# WBZ351 register map
Vendor: Microchip
Registers are 32-bit, read-write, reset 0x0 unless marked. A register's access mark holds for its fields unless they carry their own. Addresses are absolute, and some are shared; only a register's first bit layout is shown; [hi:lo] are bit positions; 'fields as' and 'values as' point back to an identical list.

## SILEX
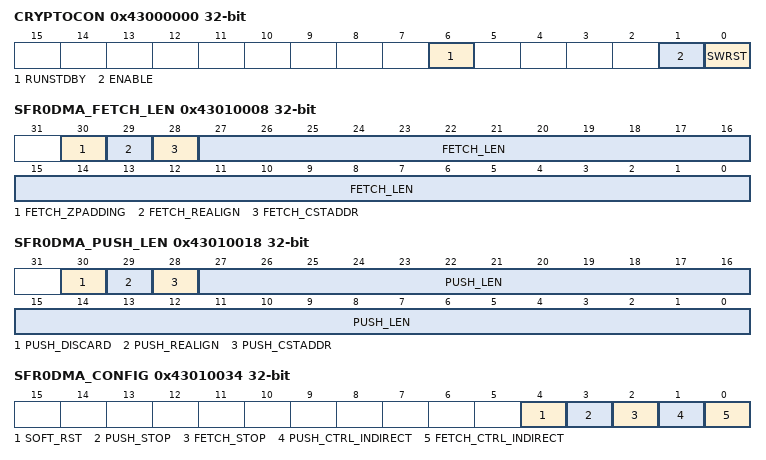
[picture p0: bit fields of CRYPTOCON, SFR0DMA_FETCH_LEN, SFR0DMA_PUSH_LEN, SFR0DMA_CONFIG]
0x43000000 CRYPTOCON
  [6] RUNSTDBY — Enable clock in idle mode
  [1] ENABLE — Enable clock to SILEX
  [0] SWRST — Software Reset
0x43010000 SFR0DMA_FETCH_ADDR_LSB
  [31:0] FETCH_ADDR_LSB
0x43010004 SFR0DMA_FETCH_ADDR_MSB
  [31:0] FETCH_ADDR_MSB
0x43010008 SFR0DMA_FETCH_LEN
  [30] FETCH_ZPADDING, [29] FETCH_REALIGN, [28] FETCH_CSTADDR, [27:0] FETCH_LEN
0x4301000C SFR0DMA_FETCH_TAG
  [31:0] FETCH_TAG
0x43010010 SFR0DMA_PUSH_ADDR_LSB
  [31:0] PUSH_ADDR_LSB
0x43010014 SFR0DMA_PUSH_ADDR_MSB
  [31:0] PUSH_ADDR_MSB
0x43010018 SFR0DMA_PUSH_LEN
  [30] PUSH_DISCARD, [29] PUSH_REALIGN, [28] PUSH_CSTADDR, [27:0] PUSH_LEN
0x4301001C SFR0DMA_INT_EN
  [31:0] INT_EN
0x43010020 SFR0DMA_INT_ENSET wo
  [31:0] INT_ENSET
0x43010024 SFR0DMA_INT_ENCLR wo
  [31:0] INT_ENCLR
0x43010028 SFR0DMA_INT_STATRAW ro
  [31:0] INT_STATRAW
0x4301002C SFR0DMA_INT_STAT ro
  [31:0] INT_STAT
0x43010030 SFR0DMA_INT_STATCLR wo
  [31:0] INT_STATCLR
0x43010034 SFR0DMA_CONFIG
  [4] SOFT_RST, [3] PUSH_STOP, [2] FETCH_STOP, [1] PUSH_CTRL_INDIRECT, [0] FETCH_CTRL_INDIRECT
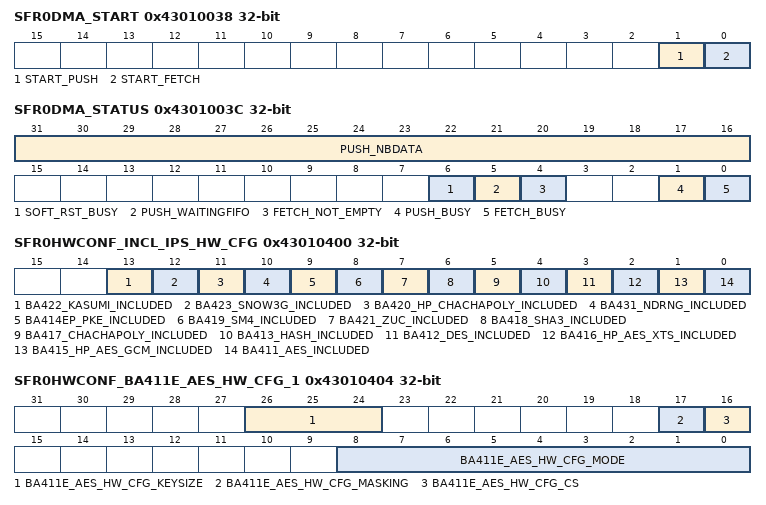
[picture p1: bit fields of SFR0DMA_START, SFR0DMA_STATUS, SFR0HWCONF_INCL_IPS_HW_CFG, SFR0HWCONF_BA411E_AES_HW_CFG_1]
0x43010038 SFR0DMA_START wo
  [1] START_PUSH, [0] START_FETCH
0x4301003C SFR0DMA_STATUS ro
  [31:16] PUSH_NBDATA, [6] SOFT_RST_BUSY, [5] PUSH_WAITINGFIFO, [4] FETCH_NOT_EMPTY, [1] PUSH_BUSY, [0] FETCH_BUSY
0x43010400 SFR0HWCONF_INCL_IPS_HW_CFG ro
  [13] BA422_KASUMI_INCLUDED — Generic g_IncludeKasumi value. BA422-Kasumi IP included if set
  [12] BA423_SNOW3G_INCLUDED — Generic g_IncludeSnow3G value. BA423-Snow3G IP included if set
  [11] BA420_HP_CHACHAPOLY_INCLUDED — Generic g_IncludeHPChachaPoly value. BA420-HP-ChaChaPoly IP included if set
  [10] BA431_NDRNG_INCLUDED — Generic g_IncludeNDRNG value. BA431-NDRNG IP included if set
  [9] BA414EP_PKE_INCLUDED — Generic g_IncludePKE value. BA414EP-PKE IP included if set
  [8] BA419_SM4_INCLUDED — Generic g_IncludeSM4 value. BA419-SM4 IP included if set
  [7] BA421_ZUC_INCLUDED — Generic g_IncludeZUC value. BA421-ZUC IP included if set
  [6] BA418_SHA3_INCLUDED — Generic g_IncludeSHA3 value. BA418-SHA3 IP included if set
  [5] BA417_CHACHAPOLY_INCLUDED — Generic g_IncludeChachaPoly value. BA417-ChaChaPoly IP included if set
  [4] BA413_HASH_INCLUDED — Generic g_IncludeHASH value. BA413-HASH IP included if set
  [3] BA412_DES_INCLUDED — Generic g_IncludeDES value. BA412-3DES IP included if set
  [2] BA416_HP_AES_XTS_INCLUDED — Generic g_IncludeAESXTS value. BA416-HP-AES-XTS IP included if set
  [1] BA415_HP_AES_GCM_INCLUDED — Generic g_IncludeAESGCM value. BA415-HP-AES-GCM IP included if set
  [0] BA411_AES_INCLUDED — Generic g_IncludeAES value. BA411E-AES IP included if set
0x43010404 SFR0HWCONF_BA411E_AES_HW_CFG_1 ro
  [26:24] BA411E_AES_HW_CFG_KEYSIZE — Generic g_Keysize value. BA411E-AES engine configuration.
  [17] BA411E_AES_HW_CFG_MASKING — Generic g_UseMasking value. BA411E-AES engine configuration.
  [16] BA411E_AES_HW_CFG_CS — Generic g_CS value. BA411E-AES engine configuration.
  [8:0] BA411E_AES_HW_CFG_MODE — Generic g_AesModesPoss value. BA411E-AES engine configuration.
0x43010408 SFR0HWCONF_BA411E_AES_HW_CFG_2 ro
  [15:0] BA411E_AES_HW_CFG_2 — Generic g_CtrSize value. BA411E-AES engine configuration.
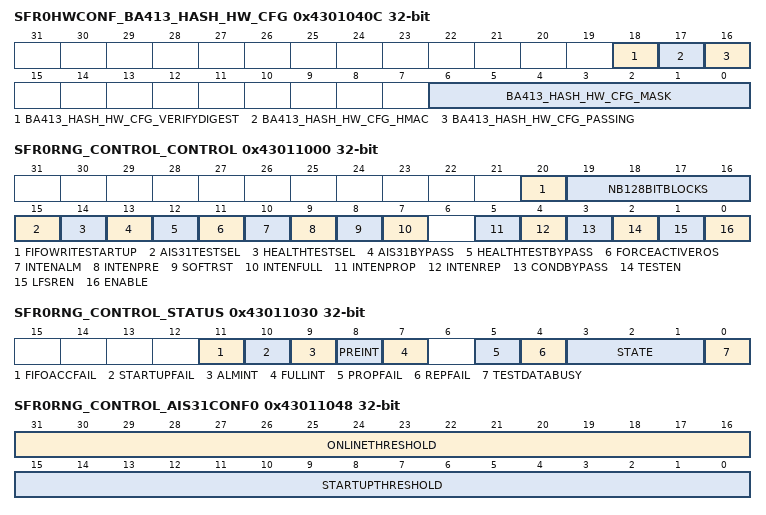
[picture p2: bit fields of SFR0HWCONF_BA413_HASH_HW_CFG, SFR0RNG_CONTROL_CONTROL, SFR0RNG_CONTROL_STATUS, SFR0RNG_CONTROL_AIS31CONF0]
0x4301040C SFR0HWCONF_BA413_HASH_HW_CFG ro
  [18] BA413_HASH_HW_CFG_VERIFYDIGEST — Generic g_HashVerifyDigest value. BA413-Hash engine configuration.
  [17] BA413_HASH_HW_CFG_HMAC — Generic g_HMAC_enabled value. BA413-Hash engine configuration.
  [16] BA413_HASH_HW_CFG_PASSING — Generic g_HashPadding value. BA413-Hash engine configuration.
  [6:0] BA413_HASH_HW_CFG_MASK — Generic g_HashMaskFunc value. BA413-Hash engine configuration.
0x43010410 SFR0HWCONF_BA418_SHA3_HW_CFG ro
  [0] BA418_SHA3_HW_CFG — Generic g_Sha3CtxtEn value. BA418-SHA3 configuration.
0x43010414 SFR0HWCONF_BA419_SM4_HW_CFG ro
  [6:0] BA419_SM4_HW_CFG — Generic g_SM4ModesPoss value. BA419-SM4 engine configuration.
0x43010418 SFR0HWCONF_BA424_ARIA_HW_CFG ro
  [8:0] BA424_ARIA_HW_CFG — Generic g_aria_modePoss value. BA424-Aria engine configuration.
0x43011000 SFR0RNG_CONTROL_CONTROL
  [20] FIFOWRITESTARTUP — Enable write of the samples in the FIFO during start-up.
  [19:16] NB128BITBLOCKS — Number of 128 bit blocks used in AES-CBCMAC post-processing. This value cannot be zero.
  [15] AIS31TESTSEL — Select input to the AIS31 test module: 0: Before conditioning, 1: After conditioning.
  [14] HEALTHTESTSEL — Select input to health test module: 0: Before conditioning, 1: After conditioning.
  [13] AIS31BYPASS — Bypass AIS31 tests such that the results of the start-up and online tests do not affect the FSM state.
  [12] HEALTHTESTBYPASS — Bypass NIST tests such that the results of the start-up and online test do not affect the FSM state.
  [11] FORCEACTIVEROS — Force oscillators to run when FIFO is full.
  [10] INTENALM — Interrupt enable for AIS31 noise alarm.
  [9] INTENPRE — Interrupt enable for AIS31 preliminary noise alarm.
  [8] SOFTRST — Software reset: 0: Normal mode, 1: The continuous test, the conditioning function and the FIFO are reset. This bit is not cleared automatically.
  [7] INTENFULL — Interrupt enable for FIFO full.
  [5] INTENPROP — Interrupt enable for Adaptive Proportion Test failure (1024-sample window).
  [4] INTENREP — Interrupt enable for Repetition Count Test failure.
  [3] CONDBYPASS — 0: the conditioning function is used (normal mode), 1: the conditioning function is bypassed (to observe entropy source directly).
  [2] TESTEN — Select input for conditioning function and continuous tests: 0: Noise source (normal mode), 1: Test data register (test mode).
  [1] LFSREN — Select between the NDRNG with asynchronous free running oscillators (when '0') and the Pseudo-Random generator with synchronous oscillators for simulation purpose (when '1').
  [0] ENABLE — Enable the NDRNG.
0x43011004 SFR0RNG_CONTROL_FIFOLEVEL
  [31:0] FIFOLEVEL — Number of 32 bits words of random available in the FIFO. Any write to this register clears the FullInt flag in the Status register.
0x43011008 SFR0RNG_CONTROL_FIFOTHRESHOLD
  [31:0] FIFOTHRESHOLD — FIFO level below which the module leaves the idle state to refill the FIFO, expressed in number of 128bit blocks.
0x4301100C SFR0RNG_CONTROL_FIFODEPTH ro
  [31:0] FIFODEPTH — Maximum number of 32 bits words that can be stored in the FIFO: 2**g_fifodepth.
0x43011010 SFR0RNG_CONTROL_KEY0
  [31:0] KEY0 — Key register (MSB).
0x43011014 SFR0RNG_CONTROL_KEY1
  [31:0] KEY1 — Key register.
0x43011018 SFR0RNG_CONTROL_KEY2
  [31:0] KEY2 — Key register.
0x4301101C SFR0RNG_CONTROL_KEY3
  [31:0] KEY3 — Key register (LSB).
0x43011020 SFR0RNG_CONTROL_TESTDATA wo
0x43011024 SFR0RNG_CONTROL_REPEATTHRESHOLD
  [31:0] REPEATTHRESHOLD — Repetition Test Count Cut-Off value.
0x43011028 SFR0RNG_CONTROL_PROPTHRESHOLD
  [31:0] PROPTHRESHOLD — Adaptive Proportion Test (1024-sample window) Cut-Off value.
0x43011030 SFR0RNG_CONTROL_STATUS
  [11] FIFOACCFAIL — Set when a FIFO data read is performed while the NDRNG is disabled AND has its FIFO empty (FIFOLevel = 0).
  [10] STARTUPFAIL — Start-up test failure.
  [9] ALMINT — AIS31 noise alarm interrupt status.
  [8] PREINT — AIS31 preliminary noise alarm interrupt status.
  [7] FULLINT — FIFO full status.
  [5] PROPFAIL — NIST-800-90B adaptive Proportion Test (1024-sample window) interrupt status.
  [4] REPFAIL — NIST-800-90B repetition Count Test interrupt status.
  [3:1] STATE — State of the control FSM: 000: Reset, 001: Startup, 010: Idle (Rings On), 011: Idle (Rings Off), 100: Fill FIFO, 101: Error, 110: Unused, 111: Unused.
  [0] TESTDATABUSY — High when data written to TestData register is being processed. (see section 4.7)
0x43011034 SFR0RNG_CONTROL_INITWAITVAL reset 0xFFFF
  [15:0] INITWAITVAL — Number of clock cycles to wait before sampling data from the noise source.
0x43011038 SFR0RNG_CONTROL_DISABLEOSC0
  [31:0] DISABLEOSC0 — Disable oscillator rings #0 to #31.
0x4301103C SFR0RNG_CONTROL_DISABLEOSC1
  [31:0] DISABLEOSC1 — Disable oscillator rings #32 to #63.
0x43011040 SFR0RNG_CONTROL_SWOFFTMRVAL
  [15:0] SWOFFTMRVAL — Number of clk cycles to wait before stopping the rings after the FIFO is full.
0x43011044 SFR0RNG_CONTROL_CLKDIV
  [7:0] CLKDIV — Sample clock divider. The frequency at which the outputs of the rings are sampled is given by: Fs=Fpclk/(ClkDiv+1).
0x43011048 SFR0RNG_CONTROL_AIS31CONF0
  [31:16] ONLINETHRESHOLD
  [15:0] STARTUPTHRESHOLD — Start-up test threshold.
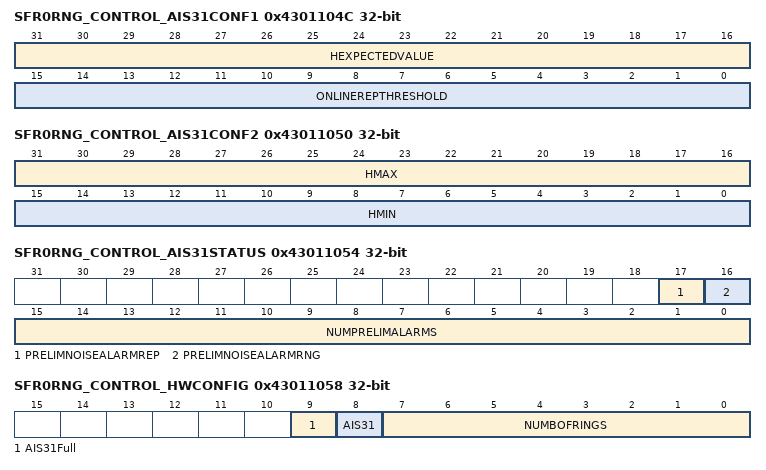
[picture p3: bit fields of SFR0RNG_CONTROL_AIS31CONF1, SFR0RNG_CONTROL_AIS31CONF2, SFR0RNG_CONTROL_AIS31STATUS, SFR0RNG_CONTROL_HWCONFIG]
0x4301104C SFR0RNG_CONTROL_AIS31CONF1
  [31:16] HEXPECTEDVALUE — Expected history value.
  [15:0] ONLINEREPTHRESHOLD — Online repeat threshold.
0x43011050 SFR0RNG_CONTROL_AIS31CONF2
  [31:16] HMAX — Maximum allowed history value.
  [15:0] HMIN — Minimum allowed history value.
0x43011054 SFR0RNG_CONTROL_AIS31STATUS
  [17] PRELIMNOISEALARMREP — Last preliminary noise alarm occurred due to consecutive high X**2.
  [16] PRELIMNOISEALARMRNG — Last preliminary noise alarm occurred due to history value out of range.
  [15:0] NUMPRELIMALARMS — Number of preliminary noise alarms since counter was last cleared.
0x43011058 SFR0RNG_CONTROL_HWCONFIG ro
  [9] AIS31Full — Generic g_AIS31Full value.
  [8] AIS31 — Generic g_AIS31 value.
  [7:0] NUMBOFRINGS — Generic g_NumRings value.
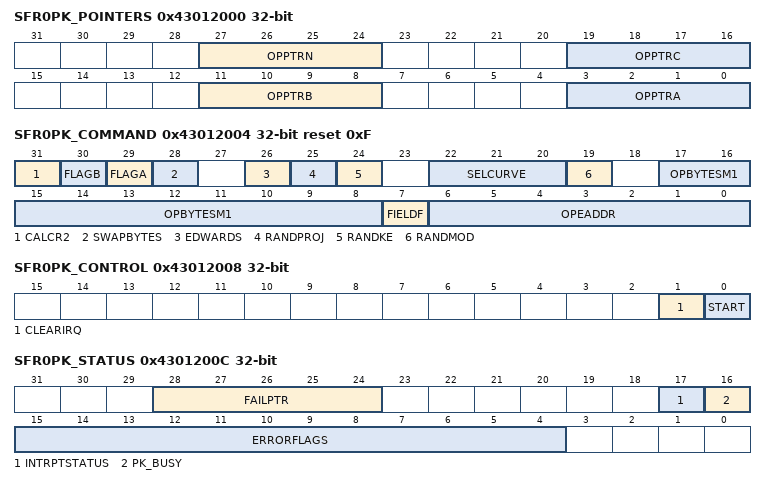
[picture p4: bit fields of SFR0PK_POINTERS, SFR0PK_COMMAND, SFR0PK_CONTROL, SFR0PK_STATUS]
0x43012000 SFR0PK_POINTERS
  [27:24] OPPTRN — When executing primitive arithmetic operations, this pointer defines the location where the modulus is located in memory (location 0x0 to 0xF).
  [19:16] OPPTRC — When executing primitive arithmetic operations, this pointer defines the location (0x0 to 0xF) where the result will be stored in memory.
  [11:8] OPPTRB — When executing primitive arithmetic operations, this pointer defines where operand B is located in memory (location 0x0 to 0xF).
  [3:0] OPPTRA — When executing primitive arithmetic operations, this pointer defines where operand A is located in memory (location 0x0 to 0xF).
0x43012004 SFR0PK_COMMAND reset 0xF
  [31] CALCR2 — This bit indicates if the IP has to calculate R**2 mod N for the next operation. This bit must be set to '1' when a new prime number has been programmed. This bit is used for primitive operations and ignored for the other operations. '0': don't recalculate R**2 mod N '1': re-calculate R**2 mod N
  [30] FLAGB — See operation description.
  [29] FLAGA — See operation description.
  [28] SWAPBYTES — Swap the bytes on AHB interface: '0': Native format (little endian) '1': Byte swapped (big endian) See also section 4.2.1. This bit must be programmed before writing/reading any data in data memory.
  [26] EDWARDS — Enable Edwards curve (see operation description).
  [25] RANDPROJ — Enable randomization of projective coordinates (counter-measure).
  [24] RANDKE — Enable randomization of exponent/scalar (counter-measure).
  [22:20] SELCURVE — Enable accelerator for specific curve modulus: 0x0: No acceleration (default) 0x1: P256 0x2: P384 0x3: P521 0x4: P192 0x5: Curve25519 0x6: Ed25519 This field has no effect when the optional acceleration hardware is not included.
  [19] RANDMOD — Enable randomization of modulus (counter-measure).
  [17:8] OPBYTESM1 — This field defines the size (= number of bytes minus one) of the operands for the current operation. Possible values are limited by the maximum supported operand size. Examples: - 0x014 -> ECC on curve K-163 - 0x01F -> ECC on curve P-256 - 0x02F -> ECC on curve P-384 - 0x033 -> ECC on curve K-409 - 0x041 -> ECC on curve P-521 - 0x07F -> 1024-bit RSA - 0x09F -> 1280-bit RSA - 0x1FF -> 4096-bit RSA - 0x3FF -> 8192-bit RSA
  [7] FIELDF — '0': Field is GF(p) '1': Field is GF(2**m)
  [6:0] OPEADDR — This field defines the operation to be performed. See documentation for more details.
0x43012008 SFR0PK_CONTROL wo
  [1] CLEARIRQ — Writing a '1' clears the IRQ output.
  [0] START — Writing a '1' starts the processing.
0x4301200C SFR0PK_STATUS ro
  [28:24] FAILPTR — These bits indicate which data location generated the error flag. They are not available for all error flags.
  [17] INTRPTSTATUS — This bit reflects the IRQ output value. It is set when the operation is finished. It is cleared when the CPU writes the bit 1 of Control Register.
  [16] PK_BUSY — This bit reflects the BUSY output value. It is set when the operation starts and it is cleared when the operation is finished.
  [15:4] ERRORFLAGS — These bits indicate an error condition. They are updated at the end of the operation. They are cleared when starting a new operation. See documentation for more details.
0x43012014 SFR0PK_TIMER
  [31:0] TIMER — Number of core clock cycles.
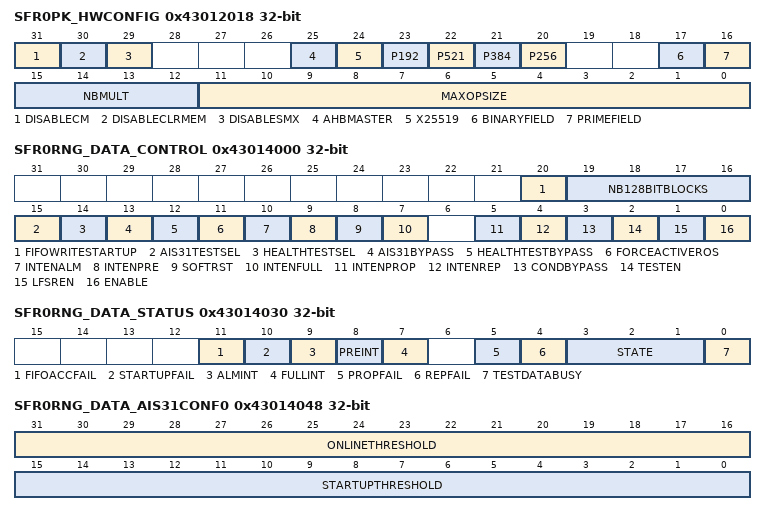
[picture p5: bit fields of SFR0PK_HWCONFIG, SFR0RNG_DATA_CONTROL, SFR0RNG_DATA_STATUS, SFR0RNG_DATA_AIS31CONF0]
0x43012018 SFR0PK_HWCONFIG ro
  [31] DISABLECM — State of DisableCM input (high when counter-measures are disabled).
  [30] DISABLECLRMEM — State of DisableClrMem input (high when automatic clear of the RAM after reset is disabled).
  [29] DISABLESMX — State of DisableSMx input (high when SM2/SM9 operations are disabled).
  [25] AHBMASTER — '0': Memory access through AHB Slave and internally in the PKE. '1': Memory access through AHB Master, outside the PKE.
  [24] X25519 — Support Curve25519/Ed25519 acceleration.
  [23] P192 — Support ECC P192 acceleration.
  [22] P521 — Support ECC P521 acceleration.
  [21] P384 — Support ECC P384 acceleration.
  [20] P256 — Support ECC P256 acceleration.
  [17] BINARYFIELD — Support binary field.
  [16] PRIMEFIELD — Support prime field.
  [15:12] NBMULT — Number of multipliers: 0x0: 1 multiplier 0x1: 4 multipliers 0x2: 16 multipliers 0x4: 64 multipliers 0x8: 256 multipliers
  [11:0] MAXOPSIZE — Maximum operand size (number of bytes).
0x4301201C SFR0PK_OPSIZE reset 0x1000
  [12:0] OPSIZE — Operand size (number of bytes): 0x0100: 256 0x0209: 521 0x0800: 2048 0x0C00: 3072 0x1000: 4096 This register is used when the memory is accessed via AHB Master
0x43012020 SFR0PK_MEMOFFSET
  [31:0] MEMOFFSET — Memory offset for AHB Master
0x43012024 SFR0PK_MICROCODEOFFSET
  [31:0] MICROCODEOFFSET — MicroCode offset for AHB Master
0x43014000 SFR0RNG_DATA_CONTROL
  fields as SFR0RNG_CONTROL_CONTROL
0x43014004 SFR0RNG_DATA_FIFOLEVEL
  fields as SFR0RNG_CONTROL_FIFOLEVEL
0x43014008 SFR0RNG_DATA_FIFOTHRESHOLD
  fields as SFR0RNG_CONTROL_FIFOTHRESHOLD
0x4301400C SFR0RNG_DATA_FIFODEPTH ro
  fields as SFR0RNG_CONTROL_FIFODEPTH
0x43014010 SFR0RNG_DATA_KEY0
  [31:0] KEY0 — Key register (MSB).
0x43014014 SFR0RNG_DATA_KEY1
  [31:0] KEY1 — Key register.
0x43014018 SFR0RNG_DATA_KEY2
  [31:0] KEY2 — Key register.
0x4301401C SFR0RNG_DATA_KEY3
  [31:0] KEY3 — Key register (LSB).
0x43014020 SFR0RNG_DATA_TESTDATA wo
0x43014024 SFR0RNG_DATA_REPEATTHRESHOLD
  [31:0] REPEATTHRESHOLD — Repetition Test Count Cut-Off value.
0x43014028 SFR0RNG_DATA_PROPTHRESHOLD
  fields as SFR0RNG_CONTROL_PROPTHRESHOLD
0x43014030 SFR0RNG_DATA_STATUS
  fields as SFR0RNG_CONTROL_STATUS
0x43014034 SFR0RNG_DATA_INITWAITVAL reset 0xFFFF
  fields as SFR0RNG_CONTROL_INITWAITVAL
0x43014038 SFR0RNG_DATA_DISABLEOSC0
  [31:0] DISABLEOSC0 — Disable oscillator rings #0 to #31.
0x4301403C SFR0RNG_DATA_DISABLEOSC1
  [31:0] DISABLEOSC1 — Disable oscillator rings #32 to #63.
0x43014040 SFR0RNG_DATA_SWOFFTMRVAL
  fields as SFR0RNG_CONTROL_SWOFFTMRVAL
0x43014044 SFR0RNG_DATA_CLKDIV
  fields as SFR0RNG_CONTROL_CLKDIV
0x43014048 SFR0RNG_DATA_AIS31CONF0
  fields as SFR0RNG_CONTROL_AIS31CONF0
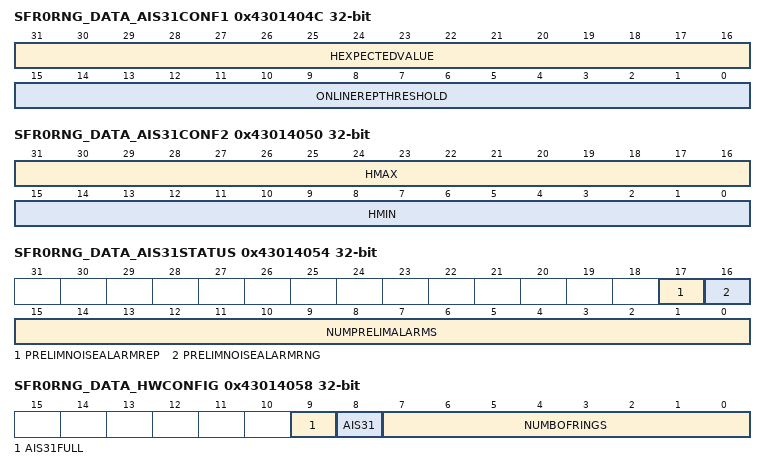
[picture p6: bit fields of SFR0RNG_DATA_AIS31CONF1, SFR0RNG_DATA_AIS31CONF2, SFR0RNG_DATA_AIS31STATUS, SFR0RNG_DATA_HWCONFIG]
0x4301404C SFR0RNG_DATA_AIS31CONF1
  fields as SFR0RNG_CONTROL_AIS31CONF1
0x43014050 SFR0RNG_DATA_AIS31CONF2
  fields as SFR0RNG_CONTROL_AIS31CONF2
0x43014054 SFR0RNG_DATA_AIS31STATUS
  fields as SFR0RNG_CONTROL_AIS31STATUS
0x43014058 SFR0RNG_DATA_HWCONFIG ro
  [9] AIS31FULL — Generic g_AIS31Full value.
  [8] AIS31 — Generic g_AIS31 value.
  [7:0] NUMBOFRINGS — Generic g_NumRings value.
